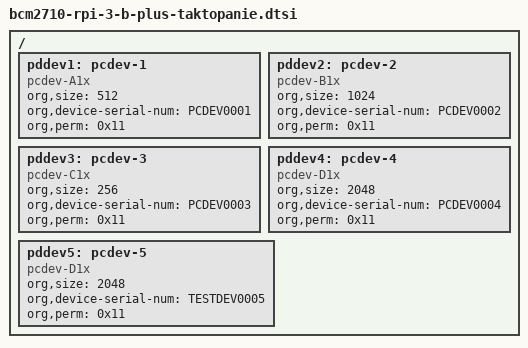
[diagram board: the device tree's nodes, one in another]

/ {
	pddev1: pcdev-1 {
		compatible = "pcdev-A1x";
		org,size = <512>;
		org,device-serial-num = "PCDEV0001";
		org,perm = <0x11>;
	};

        pddev2: pcdev-2 {
		compatible = "pcdev-B1x";
                org,size = <1024>;
                org,device-serial-num = "PCDEV0002";
                org,perm = <0x11>;
        };

        pddev3: pcdev-3 {
		compatible = "pcdev-C1x";	
                org,size = <256>;
                org,device-serial-num = "PCDEV0003";
                org,perm = <0x11>;
        };

        pddev4: pcdev-4 {
		compatible = "pcdev-D1x","pcdev-A1x";
                org,size = <2048>;
                org,device-serial-num = "PCDEV0004";
                org,perm = <0x11>;
        };

        pddev5: pcdev-5 {
		compatible = "pcdev-D1x","pcdev-A1x";
                org,size = <2048>;
                org,device-serial-num = "TESTDEV0005";
                org,perm = <0x11>;
        };

};
